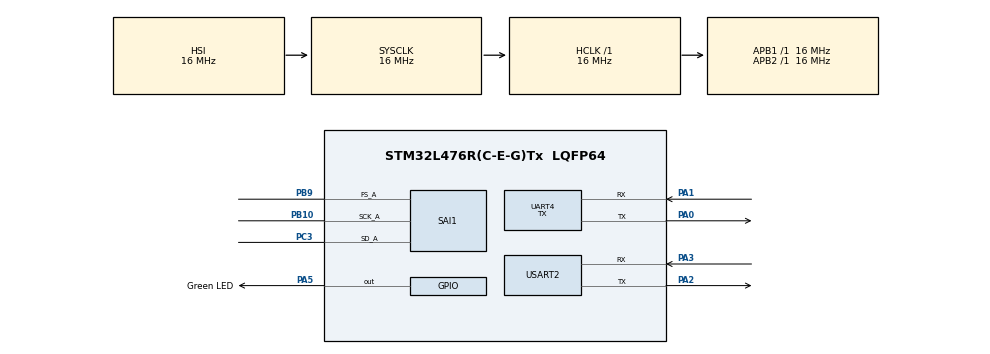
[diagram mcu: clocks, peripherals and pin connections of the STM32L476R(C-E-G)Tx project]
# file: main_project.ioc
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Dma.Request0=SAI1_A
Dma.Request1=UART4_TX
Dma.Request2=USART2_TX
Dma.SAI1_A.0.Direction=DMA_PERIPH_TO_MEMORY
Dma.SAI1_A.0.Instance=DMA2_Channel1
Dma.SAI1_A.0.MemDataAlignment=DMA_MDATAALIGN_WORD
Dma.SAI1_A.0.MemInc=DMA_MINC_ENABLE
Dma.SAI1_A.0.Mode=DMA_CIRCULAR
Dma.SAI1_A.0.PeriphDataAlignment=DMA_PDATAALIGN_WORD
Dma.SAI1_A.0.PeriphInc=DMA_PINC_DISABLE
Dma.SAI1_A.0.Priority=DMA_PRIORITY_LOW
Dma.UART4_TX.1.Direction=DMA_MEMORY_TO_PERIPH
Dma.UART4_TX.1.Instance=DMA2_Channel3
Dma.UART4_TX.1.MemDataAlignment=DMA_MDATAALIGN_BYTE
Dma.UART4_TX.1.MemInc=DMA_MINC_ENABLE
Dma.UART4_TX.1.Mode=DMA_NORMAL
Dma.UART4_TX.1.PeriphDataAlignment=DMA_PDATAALIGN_BYTE
Dma.UART4_TX.1.PeriphInc=DMA_PINC_DISABLE
Dma.UART4_TX.1.Priority=DMA_PRIORITY_HIGH
Dma.USART2_TX.2.Direction=DMA_MEMORY_TO_PERIPH
Dma.USART2_TX.2.Instance=DMA1_Channel7
Dma.USART2_TX.2.MemDataAlignment=DMA_MDATAALIGN_BYTE
Dma.USART2_TX.2.MemInc=DMA_MINC_ENABLE
Dma.USART2_TX.2.Mode=DMA_NORMAL
Dma.USART2_TX.2.PeriphDataAlignment=DMA_PDATAALIGN_BYTE
Dma.USART2_TX.2.PeriphInc=DMA_PINC_DISABLE
Dma.USART2_TX.2.Priority=DMA_PRIORITY_HIGH
Mcu.Family=STM32L4
Mcu.Name=STM32L476R(C-E-G)Tx
Mcu.Package=LQFP64
NVIC.DMA1_Channel7_IRQn=true\:0\:0\:false\:false\:true\:false\:true\:true
NVIC.DMA2_Channel1_IRQn=true\:0\:0\:false\:false\:true\:false\:true\:true
NVIC.DMA2_Channel3_IRQn=true\:0\:0\:false\:false\:true\:false\:true\:true
NVIC.PriorityGroup=NVIC_PRIORITYGROUP_4
NVIC.SAI1_IRQn=true\:0\:0\:false\:false\:true\:true\:true\:true
NVIC.TIM7_IRQn=true\:0\:0\:false\:false\:true\:true\:true\:true
NVIC.UART4_IRQn=true\:0\:0\:false\:false\:true\:true\:true\:true
NVIC.USART2_IRQn=true\:0\:0\:false\:false\:true\:true\:true\:true
PA0.Mode=Asynchronous
PA0.Signal=UART4_TX
PA1.Mode=Asynchronous
PA1.Signal=UART4_RX
PA2.Mode=Asynchronous
PA2.Signal=USART2_TX
PA3.Mode=Asynchronous
PA3.Signal=USART2_RX
PA5.GPIO_Label=Green LED
PA5.Signal=GPIO_Output
PB10.Mode=SAI_A_Master
PB10.Signal=SAI1_SCK_A
PB9.Mode=SAI_A_Master
PB9.Signal=SAI1_FS_A
PC3.Mode=SAI_A_Master
PC3.Signal=SAI1_SD_A
ProjectManager.HeapSize=0x200
ProjectManager.StackSize=0x400
ProjectManager.TargetToolchain=STM32CubeIDE
RCC.ADCFreq_Value=32000000
RCC.AHBFreq_Value=16000000
RCC.APB1Freq_Value=16000000
RCC.APB1TimFreq_Value=16000000
RCC.APB2Freq_Value=16000000
RCC.APB2TimFreq_Value=16000000
RCC.CortexFreq_Value=16000000
RCC.HCLKFreq_Value=16000000
RCC.HSE_VALUE=8000000
RCC.HSI_VALUE=16000000
RCC.LSE_VALUE=32768
RCC.MSI_VALUE=4000000
RCC.PLLSAI1N=16
RCC.SYSCLKFreq_VALUE=16000000
RCC.SYSCLKSource=RCC_SYSCLKSOURCE_HSI
RCC.USBFreq_Value=32000000
RCC.VCOOutputFreq_Value=32000000
SAI1.AudioFrequency-SAI_A_Master=SAI_AUDIO_FREQUENCY_16K
SAI1.AudioMode-SAI_A_Master=SAI_MODEMASTER_RX
SAI1.ClockStrobing-SAI_A_Master=SAI_CLOCKSTROBING_RISINGEDGE
SAI1.DataSize-SAI_A_Master=SAI_DATASIZE_32
SAI1.ErrorAudioFreq-SAI_A_Master=11.6 %
SAI1.FIFOThreshold-SAI_A_Master=SAI_FIFOTHRESHOLD_HF
SAI1.FSOffset-SAI_A_Master=SAI_FS_BEFOREFIRSTBIT
SAI1.FSPolarity-SAI_A_Master=SAI_FS_ACTIVE_HIGH
SAI1.FrameLength-SAI_A_Master=64
SAI1.Instance-SAI_A_Master=SAI$Index_Block_A
SAI1.MClockEnable-SAI_A_Master=SAI_MASTERCLOCK_DISABLE
SAI1.RealAudioFreq-SAI_A_Master=17.857 KHz
SAI1.SlotActive-SAI_A_Master=0x00000001
SAI1.SlotNumber-SAI_A_Master=2
SAI1.SlotSize-SAI_A_Master=SAI_SLOTSIZE_32B
SAI1.VirtualMode-SAI_A_Master=VM_MASTER
SAI1.VirtualSlotActive-SAI_A_Master=SAI_SLOT_USERSETTING
SAI1.VirtualSlotActive0-SAI_A_Master=true
SAI1.VirtualSlotActive1-SAI_A_Master=false
TIM7.Period=4999
TIM7.Prescaler=15999
UART4.Mode=MODE_TX
USART2.VirtualMode-Asynchronous=VM_ASYNC
VP_TIM7_VS_ClockSourceINT.Mode=Enable_Timer
board=custom

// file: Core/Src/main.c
/* USER CODE BEGIN Header */
/**
  ******************************************************************************
  * @file           : main.c
  * @brief          : Main program body
  ******************************************************************************
  * @attention
  *
  * Copyright (c) 2026 STMicroelectronics.
  * All rights reserved.
  *
  * This software is licensed under terms that can be found in the LICENSE file
  * in the root directory of this software component.
  * If no LICENSE file comes with this software, it is provided AS-IS.
  *
  ******************************************************************************
  */
/* USER CODE END Header */
#include "main.h"

/* USER CODE BEGIN Includes */
#include "ics52000.h"
/* USER CODE END Includes */

SAI_HandleTypeDef hsai_BlockA1;
DMA_HandleTypeDef hdma_sai1_a;

TIM_HandleTypeDef htim7;

UART_HandleTypeDef huart4;
UART_HandleTypeDef huart2;
DMA_HandleTypeDef hdma_uart4_tx;
DMA_HandleTypeDef hdma_usart2_tx;

void SystemClock_Config(void);
static void MX_GPIO_Init(void);
static void MX_DMA_Init(void);
static void MX_SAI1_Init(void);
static void MX_TIM7_Init(void);
static void MX_USART2_UART_Init(void);
static void MX_UART4_Init(void);

int main(void)
{

  /* MCU Configuration--------------------------------------------------------*/

  /* Reset of all peripherals, Initializes the Flash interface and the Systick. */
  HAL_Init();

  /* Configure the system clock */
  SystemClock_Config();

  /* Initialize all configured peripherals */
  MX_GPIO_Init();
  MX_DMA_Init();
  MX_SAI1_Init();
  MX_TIM7_Init();
  MX_USART2_UART_Init();
  MX_UART4_Init();
  /* USER CODE BEGIN 2 */
  ics52000_start();
  /* USER CODE END 2 */

  /* Infinite loop */
  while (1)
  {

    /* USER CODE BEGIN 3 */
	ics52000_read();
  }
  /* USER CODE END 3 */
}

void SystemClock_Config(void)
{
  RCC_OscInitTypeDef RCC_OscInitStruct = {0};
  RCC_ClkInitTypeDef RCC_ClkInitStruct = {0};

  /** Configure the main internal regulator output voltage
  */
  if (HAL_PWREx_ControlVoltageScaling(PWR_REGULATOR_VOLTAGE_SCALE1) != HAL_OK)
  {
    Error_Handler();
  }

  /** Initializes the RCC Oscillators according to the specified parameters
  * in the RCC_OscInitTypeDef structure.
  */
  RCC_OscInitStruct.OscillatorType = RCC_OSCILLATORTYPE_HSI|RCC_OSCILLATORTYPE_MSI;
  RCC_OscInitStruct.HSIState = RCC_HSI_ON;
  RCC_OscInitStruct.HSICalibrationValue = RCC_HSICALIBRATION_DEFAULT;
  RCC_OscInitStruct.MSIState = RCC_MSI_ON;
  RCC_OscInitStruct.MSICalibrationValue = 0;
  RCC_OscInitStruct.MSIClockRange = RCC_MSIRANGE_6;
  RCC_OscInitStruct.PLL.PLLState = RCC_PLL_NONE;
  if (HAL_RCC_OscConfig(&RCC_OscInitStruct) != HAL_OK)
  {
    Error_Handler();
  }

  /** Initializes the CPU, AHB and APB buses clocks
  */
  RCC_ClkInitStruct.ClockType = RCC_CLOCKTYPE_HCLK|RCC_CLOCKTYPE_SYSCLK
                              |RCC_CLOCKTYPE_PCLK1|RCC_CLOCKTYPE_PCLK2;
  RCC_ClkInitStruct.SYSCLKSource = RCC_SYSCLKSOURCE_HSI;
  RCC_ClkInitStruct.AHBCLKDivider = RCC_SYSCLK_DIV1;
  RCC_ClkInitStruct.APB1CLKDivider = RCC_HCLK_DIV1;
  RCC_ClkInitStruct.APB2CLKDivider = RCC_HCLK_DIV1;

  if (HAL_RCC_ClockConfig(&RCC_ClkInitStruct, FLASH_LATENCY_0) != HAL_OK)
  {
    Error_Handler();
  }
}

static void MX_SAI1_Init(void)
{

  hsai_BlockA1.Instance = SAI1_Block_A;
  hsai_BlockA1.Init.Protocol = SAI_FREE_PROTOCOL;
  hsai_BlockA1.Init.AudioMode = SAI_MODEMASTER_RX;
  hsai_BlockA1.Init.DataSize = SAI_DATASIZE_32;
  hsai_BlockA1.Init.FirstBit = SAI_FIRSTBIT_MSB;
  hsai_BlockA1.Init.ClockStrobing = SAI_CLOCKSTROBING_RISINGEDGE;
  hsai_BlockA1.Init.Synchro = SAI_ASYNCHRONOUS;
  hsai_BlockA1.Init.OutputDrive = SAI_OUTPUTDRIVE_DISABLE;
  hsai_BlockA1.Init.NoDivider = SAI_MASTERDIVIDER_ENABLE;
  hsai_BlockA1.Init.FIFOThreshold = SAI_FIFOTHRESHOLD_HF;
  hsai_BlockA1.Init.AudioFrequency = SAI_AUDIO_FREQUENCY_16K;
  hsai_BlockA1.Init.SynchroExt = SAI_SYNCEXT_DISABLE;
  hsai_BlockA1.Init.MonoStereoMode = SAI_STEREOMODE;
  hsai_BlockA1.Init.CompandingMode = SAI_NOCOMPANDING;
  hsai_BlockA1.FrameInit.FrameLength = 64;
  hsai_BlockA1.FrameInit.ActiveFrameLength = 1;
  hsai_BlockA1.FrameInit.FSDefinition = SAI_FS_STARTFRAME;
  hsai_BlockA1.FrameInit.FSPolarity = SAI_FS_ACTIVE_HIGH;
  hsai_BlockA1.FrameInit.FSOffset = SAI_FS_BEFOREFIRSTBIT;
  hsai_BlockA1.SlotInit.FirstBitOffset = 0;
  hsai_BlockA1.SlotInit.SlotSize = SAI_SLOTSIZE_32B;
  hsai_BlockA1.SlotInit.SlotNumber = 2;
  hsai_BlockA1.SlotInit.SlotActive = 0x00000001;
  if (HAL_SAI_Init(&hsai_BlockA1) != HAL_OK)
  {
    Error_Handler();
  }

}

static void MX_TIM7_Init(void)
{

  TIM_MasterConfigTypeDef sMasterConfig = {0};

  htim7.Instance = TIM7;
  htim7.Init.Prescaler = 15999;
  htim7.Init.CounterMode = TIM_COUNTERMODE_UP;
  htim7.Init.Period = 4999;
  htim7.Init.AutoReloadPreload = TIM_AUTORELOAD_PRELOAD_DISABLE;
  if (HAL_TIM_Base_Init(&htim7) != HAL_OK)
  {
    Error_Handler();
  }
  sMasterConfig.MasterOutputTrigger = TIM_TRGO_RESET;
  sMasterConfig.MasterSlaveMode = TIM_MASTERSLAVEMODE_DISABLE;
  if (HAL_TIMEx_MasterConfigSynchronization(&htim7, &sMasterConfig) != HAL_OK)
  {
    Error_Handler();
  }

}

static void MX_UART4_Init(void)
{

  huart4.Instance = UART4;
  huart4.Init.BaudRate = 115200;
  huart4.Init.WordLength = UART_WORDLENGTH_8B;
  huart4.Init.StopBits = UART_STOPBITS_1;
  huart4.Init.Parity = UART_PARITY_NONE;
  huart4.Init.Mode = UART_MODE_TX;
  huart4.Init.HwFlowCtl = UART_HWCONTROL_NONE;
  huart4.Init.OverSampling = UART_OVERSAMPLING_16;
  huart4.Init.OneBitSampling = UART_ONE_BIT_SAMPLE_DISABLE;
  huart4.AdvancedInit.AdvFeatureInit = UART_ADVFEATURE_NO_INIT;
  if (HAL_UART_Init(&huart4) != HAL_OK)
  {
    Error_Handler();
  }

}

static void MX_USART2_UART_Init(void)
{

  huart2.Instance = USART2;
  huart2.Init.BaudRate = 115200;
  huart2.Init.WordLength = UART_WORDLENGTH_8B;
  huart2.Init.StopBits = UART_STOPBITS_1;
  huart2.Init.Parity = UART_PARITY_NONE;
  huart2.Init.Mode = UART_MODE_TX_RX;
  huart2.Init.HwFlowCtl = UART_HWCONTROL_NONE;
  huart2.Init.OverSampling = UART_OVERSAMPLING_16;
  huart2.Init.OneBitSampling = UART_ONE_BIT_SAMPLE_DISABLE;
  huart2.AdvancedInit.AdvFeatureInit = UART_ADVFEATURE_NO_INIT;
  if (HAL_UART_Init(&huart2) != HAL_OK)
  {
    Error_Handler();
  }

}

static void MX_DMA_Init(void)
{

  /* DMA controller clock enable */
  __HAL_RCC_DMA2_CLK_ENABLE();
  __HAL_RCC_DMA1_CLK_ENABLE();

  /* DMA interrupt init */
  /* DMA1_Channel7_IRQn interrupt configuration */
  HAL_NVIC_SetPriority(DMA1_Channel7_IRQn, 0, 0);
  HAL_NVIC_EnableIRQ(DMA1_Channel7_IRQn);
  /* DMA2_Channel1_IRQn interrupt configuration */
  HAL_NVIC_SetPriority(DMA2_Channel1_IRQn, 0, 0);
  HAL_NVIC_EnableIRQ(DMA2_Channel1_IRQn);
  /* DMA2_Channel3_IRQn interrupt configuration */
  HAL_NVIC_SetPriority(DMA2_Channel3_IRQn, 0, 0);
  HAL_NVIC_EnableIRQ(DMA2_Channel3_IRQn);

}

static void MX_GPIO_Init(void)
{
  GPIO_InitTypeDef GPIO_InitStruct = {0};

  /* GPIO Ports Clock Enable */
  __HAL_RCC_GPIOC_CLK_ENABLE();
  __HAL_RCC_GPIOA_CLK_ENABLE();
  __HAL_RCC_GPIOB_CLK_ENABLE();

  /*Configure GPIO pin Output Level */
  HAL_GPIO_WritePin(Green_LED_GPIO_Port, Green_LED_Pin, GPIO_PIN_RESET);

  /*Configure GPIO pin : Green_LED_Pin */
  GPIO_InitStruct.Pin = Green_LED_Pin;
  GPIO_InitStruct.Mode = GPIO_MODE_OUTPUT_PP;
  GPIO_InitStruct.Pull = GPIO_NOPULL;
  GPIO_InitStruct.Speed = GPIO_SPEED_FREQ_LOW;
  HAL_GPIO_Init(Green_LED_GPIO_Port, &GPIO_InitStruct);

}

void Error_Handler(void)
{
  __disable_irq();
  while (1)
  {
  }
}
